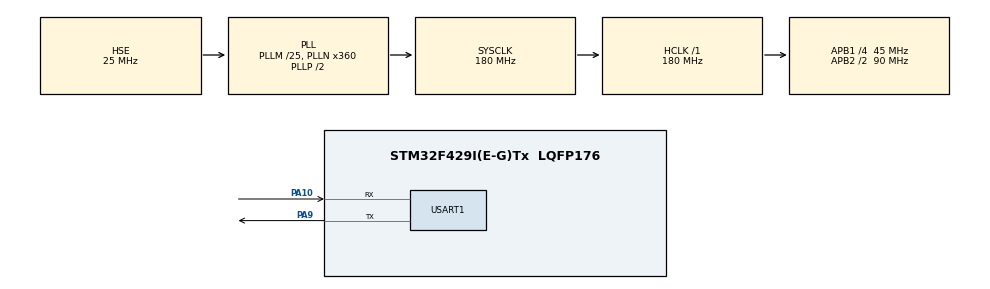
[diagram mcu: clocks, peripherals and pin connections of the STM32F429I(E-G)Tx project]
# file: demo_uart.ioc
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Mcu.Family=STM32F4
Mcu.Name=STM32F429I(E-G)Tx
Mcu.Package=LQFP176
NVIC.PriorityGroup=NVIC_PRIORITYGROUP_4
NVIC.USART1_IRQn=true\:0\:0\:false\:false\:true\:true\:true\:true
PA10.Mode=Asynchronous
PA10.Signal=USART1_RX
PA9.Mode=Asynchronous
PA9.Signal=USART1_TX
PH0/OSC_IN.Mode=HSE-External-Oscillator
PH0/OSC_IN.Signal=RCC_OSC_IN
PH1/OSC_OUT.Mode=HSE-External-Oscillator
PH1/OSC_OUT.Signal=RCC_OSC_OUT
ProjectManager.HeapSize=0x200
ProjectManager.StackSize=0x400
ProjectManager.TargetToolchain=STM32CubeIDE
RCC.48MHZClocksFreq_Value=90000000
RCC.AHBFreq_Value=180000000
RCC.APB1CLKDivider=RCC_HCLK_DIV4
RCC.APB1Freq_Value=45000000
RCC.APB1TimFreq_Value=90000000
RCC.APB2CLKDivider=RCC_HCLK_DIV2
RCC.APB2Freq_Value=90000000
RCC.APB2TimFreq_Value=180000000
RCC.CortexFreq_Value=180000000
RCC.HCLKFreq_Value=180000000
RCC.HSE_VALUE=25000000
RCC.HSI_VALUE=16000000
RCC.LSE_VALUE=32768
RCC.PLLM=25
RCC.PLLN=360
RCC.PLLSourceVirtual=RCC_PLLSOURCE_HSE
RCC.SYSCLKFreq_VALUE=180000000
RCC.SYSCLKSource=RCC_SYSCLKSOURCE_PLLCLK
RCC.VCOOutputFreq_Value=360000000
USART1.Parity=PARITY_ODD
USART1.VirtualMode=VM_ASYNC
USART1.WordLength=WORDLENGTH_9B
board=custom

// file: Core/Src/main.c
/* USER CODE BEGIN Header */
/**
  ******************************************************************************
  * @file           : main.c
  * @brief          : Main program body
  ******************************************************************************
  * @attention
  *
  * Copyright (c) 2025 STMicroelectronics.
  * All rights reserved.
  *
  * This software is licensed under terms that can be found in the LICENSE file
  * in the root directory of this software component.
  * If no LICENSE file comes with this software, it is provided AS-IS.
  *
  ******************************************************************************
  */
/* USER CODE END Header */
#include "main.h"
#include "usart.h"
#include "gpio.h"

/* USER CODE BEGIN PV */
extern UART_HandleTypeDef huart1;
const AppCtrl* g_appController;
/* USER CODE END PV */

void SystemClock_Config(void);

/* USER CODE BEGIN 0 */
uint32_t App_GetSysTime(void) {
    return HAL_GetTick();
}

static void CommandResponseHandler(uint8_t cmdId, bool success, const uint8_t* rspData) {
    if (success) {
        // Command executed successfully
        // You can set LEDs, update display, etc.
    } else {
        // Command failed
        // Handle error condition
    }
}

void HAL_UART_TxCpltCallback(UART_HandleTypeDef* huart) {
    if (huart->Instance == USART1) {
        DrvUart_TxCompleteCallback(huart);
    }
}

void HAL_UART_RxCpltCallback(UART_HandleTypeDef* huart) {
    if (huart->Instance == USART1) {
        DrvUart_RxCompleteCallback(huart);
    }
}
/* USER CODE END 0 */

int main(void)
{

  /* MCU Configuration--------------------------------------------------------*/

  /* Reset of all peripherals, Initializes the Flash interface and the Systick. */
  HAL_Init();

  /* Configure the system clock */
  SystemClock_Config();

  /* Initialize all configured peripherals */
  MX_GPIO_Init();
  MX_USART1_UART_Init();
  /* USER CODE BEGIN 2 */
  // uint8_t data = 0x55;
  // Initialize protocol stack
  const DrvUart* uartDriver = DrvUart_GetInstance();
  uartDriver->init(&huart1);

  g_appController = AppCtrl_GetInstance();
  if (!g_appController->init()) {
      Error_Handler();
  }
  // Example: Single channel configuration and control
  // AppCfgParams singleConfig = {
  //     .chId = 1,
  //     .outCfg = APP_FIU_LOAD_NO_FAULT,
  //     .workMode = APP_MODE_CTRL,
  //     .highTime = 0,
  //     .lowTime = 0,
  //     .cycles = 0
  // };
  // g_appController->setCfg(&singleConfig, CommandResponseHandler);
  // Configure multiple channels individually
  AppCfgParams config1 = {
        .chId = 1,
        .outCfg = APP_FIU_LOAD_NO_FAULT,
        .workMode = APP_MODE_CTRL,
        .highTime = 0,
        .lowTime = 0,
        .cycles = 0
    };

    AppCfgParams config2 = {
        .chId = 2,
        .outCfg = APP_FIU_NO_LOAD_STP,
        .workMode = APP_MODE_CTRL,
        .highTime = 0,
        .lowTime = 0,
        .cycles = 0
    };

    AppCfgParams config3 = {
        .chId = 3,
        .outCfg = APP_FIU_CAN_STG,
        .workMode = APP_MODE_CTRL,
        .highTime = 0,
        .lowTime = 0,
        .cycles = 0
    };

    // Send configuration commands for each channel
    // Add delay between commands to ensure they are sent properly
    g_appController->setCfg(&config1, CommandResponseHandler);
    HAL_Delay(50); // Wait 50ms before sending next command

    g_appController->setCfg(&config2, CommandResponseHandler);
    HAL_Delay(50); // Wait 50ms before sending next command

    g_appController->setCfg(&config3, CommandResponseHandler);
    HAL_Delay(50); // Wait 50ms before sending control command

    // Send control operation on all tracked channels (1, 2, 3)
    // Pass NULL to use tracked channels
    g_appController->ctrlOp(NULL, CommandResponseHandler);
  /* USER CODE END 2 */

  /* Infinite loop */
  while (1)
  {
	  g_appController->process();
	  HAL_Delay(100); // 100ms delay
	  // HAL_UART_Transmit(&huart1, &data, 1, 100);

  }
}

void SystemClock_Config(void)
{
  RCC_OscInitTypeDef RCC_OscInitStruct = {0};
  RCC_ClkInitTypeDef RCC_ClkInitStruct = {0};

  /** Configure the main internal regulator output voltage
  */
  __HAL_RCC_PWR_CLK_ENABLE();
  __HAL_PWR_VOLTAGESCALING_CONFIG(PWR_REGULATOR_VOLTAGE_SCALE1);

  /** Initializes the RCC Oscillators according to the specified parameters
  * in the RCC_OscInitTypeDef structure.
  */
  RCC_OscInitStruct.OscillatorType = RCC_OSCILLATORTYPE_HSE;
  RCC_OscInitStruct.HSEState = RCC_HSE_ON;
  RCC_OscInitStruct.PLL.PLLState = RCC_PLL_ON;
  RCC_OscInitStruct.PLL.PLLSource = RCC_PLLSOURCE_HSE;
  RCC_OscInitStruct.PLL.PLLM = 25;
  RCC_OscInitStruct.PLL.PLLN = 360;
  RCC_OscInitStruct.PLL.PLLP = RCC_PLLP_DIV2;
  RCC_OscInitStruct.PLL.PLLQ = 4;
  if (HAL_RCC_OscConfig(&RCC_OscInitStruct) != HAL_OK)
  {
    Error_Handler();
  }

  /** Activate the Over-Drive mode
  */
  if (HAL_PWREx_EnableOverDrive() != HAL_OK)
  {
    Error_Handler();
  }

  /** Initializes the CPU, AHB and APB buses clocks
  */
  RCC_ClkInitStruct.ClockType = RCC_CLOCKTYPE_HCLK|RCC_CLOCKTYPE_SYSCLK
                              |RCC_CLOCKTYPE_PCLK1|RCC_CLOCKTYPE_PCLK2;
  RCC_ClkInitStruct.SYSCLKSource = RCC_SYSCLKSOURCE_PLLCLK;
  RCC_ClkInitStruct.AHBCLKDivider = RCC_SYSCLK_DIV1;
  RCC_ClkInitStruct.APB1CLKDivider = RCC_HCLK_DIV4;
  RCC_ClkInitStruct.APB2CLKDivider = RCC_HCLK_DIV2;

  if (HAL_RCC_ClockConfig(&RCC_ClkInitStruct, FLASH_LATENCY_5) != HAL_OK)
  {
    Error_Handler();
  }
}

void Error_Handler(void)
{
  __disable_irq();
  while (1)
  {
  }
}
